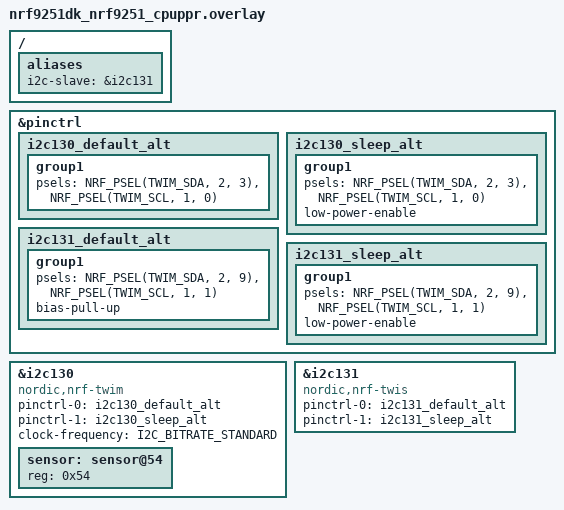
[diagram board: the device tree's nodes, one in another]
/*
 * Copyright 2026 Nordic Semiconductor ASA
 * SPDX-License-Identifier: LicenseRef-Nordic-5-Clause
 */

/*
 * Two loopbacks are required:
 * P2.03 - P2.09
 * P1.00 - P1.01
 */

/ {
	aliases {
		i2c-slave = &i2c131;
	};
};

&pinctrl {
	i2c130_default_alt: i2c130_default_alt {
		group1 {
			psels = <NRF_PSEL(TWIM_SDA, 2, 3)>,
				<NRF_PSEL(TWIM_SCL, 1, 0)>;
		};
	};

	i2c130_sleep_alt: i2c130_sleep_alt {
		group1 {
			psels = <NRF_PSEL(TWIM_SDA, 2, 3)>,
				<NRF_PSEL(TWIM_SCL, 1, 0)>;
			low-power-enable;
		};
	};

	i2c131_default_alt: i2c131_default_alt {
		group1 {
			/* Temporary workaround as it is currently not possible
			 * to configure pins for TWIS with pinctrl.
			 */
			psels = <NRF_PSEL(TWIM_SDA, 2, 9)>,
				<NRF_PSEL(TWIM_SCL, 1, 1)>;
			bias-pull-up;
		};
	};

	i2c131_sleep_alt: i2c131_sleep_alt {
		group1 {
			psels = <NRF_PSEL(TWIM_SDA, 2, 9)>,
				<NRF_PSEL(TWIM_SCL, 1, 1)>;
			low-power-enable;
		};
	};
};

dut_twim: &i2c130 {
	compatible = "nordic,nrf-twim";
	status = "okay";
	pinctrl-0 = <&i2c130_default_alt>;
	pinctrl-1 = <&i2c130_sleep_alt>;
	pinctrl-names = "default", "sleep";
	clock-frequency = <I2C_BITRATE_STANDARD>;

	sensor: sensor@54 {
		reg = <0x54>;
	};
};

&i2c131 {
	compatible = "nordic,nrf-twis";
	status = "okay";
	pinctrl-0 = <&i2c131_default_alt>;
	pinctrl-1 = <&i2c131_sleep_alt>;
	pinctrl-names = "default", "sleep";
};
